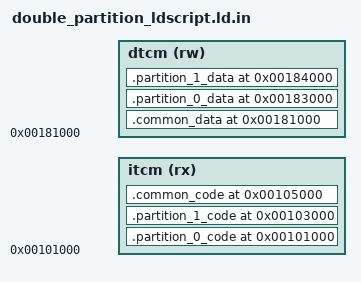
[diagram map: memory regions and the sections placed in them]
#include <liblwriscv/g_lwriscv_config.h>

OUTPUT_ARCH( "riscv" )
ENTRY(startup)
MEMORY {
    dtcm (rw) : ORIGIN = 0x0000000000181000, LENGTH = LWRISCV_APP_DMEM_LIMIT
    itcm (rx) : ORIGIN = 0x0000000000101000, LENGTH = LWRISCV_APP_IMEM_LIMIT
}
SECTIONS
{
  /DISCARD/ : 
  {
    *start.o(.text.*)
    *shutdown_m.o(.text.*)
    *exception.o(.text.*)
  }

  .partition_0_code 0x101000:
  {
      KEEP(*(.text.partition_0_startup))
      . = ALIGN(4);
      KEEP(*(.text.partition_0_trap_handler))
      *partition_0_main.o(.text.*)
      *partition_0_main.o(.rodata.* .srodata*)
      . = ALIGN(0x100);
  } > itcm

  ASSERT(. < 0x103000, "partition_0_code size too large")

  .partition_1_code 0x103000:
  {
      KEEP(*(.text.partition_1_startup))
      . = ALIGN(4);
      KEEP(*(.text.partition_1_trap_handler))
      *partition_1_main.o(.text.*)
      *partition_1_main.o(.rodata.* .srodata*)
      . = ALIGN(0x100);
  } > itcm

  ASSERT(. < 0x105000, "partition_1_code size too large")

  .common_code 0x105000 :
  {
      *shutdown_sbi.o(.text.*)
      *print.o(.text.*)
      *vprintfmt.o(.text.* .rodata .rodata.*)
      *test.o(.text.* .rodata.* .data.*)
      *.o(.text.* .rodata.* .data.*)
      . = ALIGN(0x100);
  } > itcm

  ASSERT(. < 0x108000, "common_code size too large")

  .common_data 0x181000:
  {
    *print.o(.bss.* .sbss*)
    *test.o(.bss .bss.* COMMON)
    *.o(.bss .bss.* COMMON)
      . = ALIGN(0x100);
  } > dtcm

  ASSERT(. < 0x183000, "common_data size too large")

  .partition_0_data 0x183000:
  {
    _partition_0_stack_bottom = . ;
    . += 1024 ;
    _partition_0_stack_top = . ;
    *partition_0_main.o(.data .data.* .sdata*)
    *partition_0_main.o(.bss .bss.* .sbss*)
    . = ALIGN(0x100);
  } > dtcm

  ASSERT(. < 0x184000, "partition_0_data size too large")

  .partition_1_data 0x184000:
  {
    _partition_1_stack_bottom = . ;
    . += 1024 ;
    _partition_1_stack_top = . ;
    *partition_1_main.o(.data .data.* .sdata*)
    *partition_1_main.o(.bss .bss.* .sbss*)
    . = ALIGN(0x100);
  } > dtcm

  ASSERT(. < 0x185000, "partition_1_data size too large")
}
